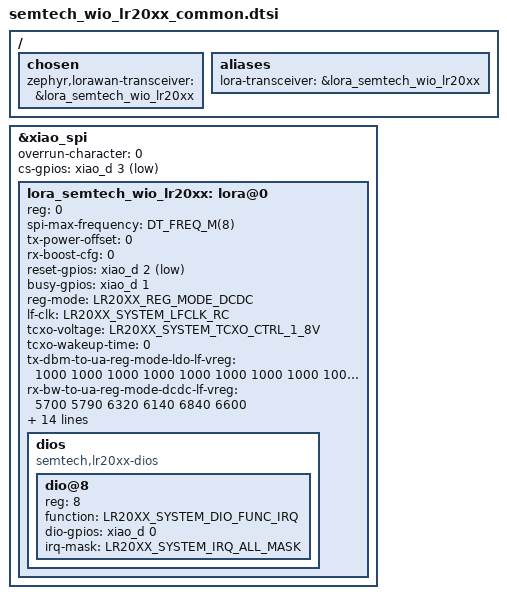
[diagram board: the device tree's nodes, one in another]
/*
 * Copyright (c) 2025 Semtech Corporation
 *
 * SPDX-License-Identifier: Apache-2.0
 */

#include <zephyr/dt-bindings/usp/lr20xx.h>

/ {
	chosen {
		zephyr,lorawan-transceiver = &lora_semtech_wio_lr20xx;
	};
	aliases {
		lora-transceiver = &lora_semtech_wio_lr20xx;
	};
};

&xiao_spi {
	status = "okay";
	overrun-character = <0>; // Defines state of MOSI when SPI RX
	cs-gpios = <&xiao_d 3 GPIO_ACTIVE_LOW>;

	lora_semtech_wio_lr20xx: lora@0 {
		reg = <0>;
		spi-max-frequency = <DT_FREQ_M(8)>;

		// Board-specific offset
		tx-power-offset = <0>;

		// RX boost offset, from 0 (no RX boost) to 7 (max RX boost)
		rx-boost-cfg = <0>;

		reset-gpios = <&xiao_d 2 GPIO_ACTIVE_LOW>; //D2

		busy-gpios = <&xiao_d 1 (GPIO_ACTIVE_HIGH | GPIO_PULL_UP)>; //D1

		reg-mode = <LR20XX_REG_MODE_DCDC>;

		lf-clk = <LR20XX_SYSTEM_LFCLK_RC>;

		tcxo-voltage = <LR20XX_SYSTEM_TCXO_CTRL_1_8V>;
		tcxo-wakeup-time = <0>;

		// LDO mode, LF path, NOT MEASed
		tx-dbm-to-ua-reg-mode-ldo-lf-vreg = <
		1000  /* -10 dBm */
		1000  /*  -9 dBm */
		1000  /*  -8 dBm */
		1000  /*  -7 dBm */
		1000  /*  -6 dBm */
		1000  /*  -5 dBm */
		1000  /*  -4 dBm */
		1000  /*  -3 dBm */
		1000  /*  -2 dBm */
		1000  /*  -1 dBm */
		1000  /*   0 dBm */
		1000  /*   1 dBm */
		1000  /*   2 dBm */
		1000  /*   3 dBm */
		1000  /*   4 dBm */
		1000  /*   5 dBm */
		1000  /*   6 dBm */
		1000  /*   7 dBm */
		1000  /*   8 dBm */
		1000  /*   9 dBm */
		1000  /*  10 dBm */
		1000  /*  11 dBm */
		1000  /*  12 dBm */
		1000  /*  13 dBm */
		1000  /*  14 dBm */
		1000  /*  15 dBm */
		1000  /*  16 dBm */
		1000  /*  17 dBm */
		1000  /*  18 dBm */
		1000  /*  19 dBm */
		1000  /*  20 dBm */
		1000  /*  21 dBm */
		1000  /*  22 dBm */
		>;

		// RX LoRa tables
		// Measured @LR20XX_RADIO_COMMON_RX_PATH_BOOST_MODE_NONE
		rx-bw-to-ua-reg-mode-dcdc-lf-vreg = <
		5700  /* RAL_LORA_BW_125_KHZ */
		5790  /* RAL_LORA_BW_250_KHZ */
		6320  /* RAL_LORA_BW_400_KHZ */
		6140  /* RAL_LORA_BW_500_KHZ */
		6840  /* RAL_LORA_BW_800_KHZ */
		6600  /* RAL_LORA_BW_1000_KHZ */
		>;

		rx-bw-to-ua-reg-mode-dcdc-hf-vreg = <
		6400  /* RAL_LORA_BW_125_KHZ */
		6510  /* RAL_LORA_BW_250_KHZ */
		7040  /* RAL_LORA_BW_400_KHZ */
		6860  /* RAL_LORA_BW_500_KHZ */
		6880  /* RAL_LORA_BW_800_KHZ */
		7350  /* RAL_LORA_BW_1000_KHZ */
		>;

		// Measured @LR20XX_RADIO_COMMON_RX_PATH_BOOST_MODE_7
		rx-bw-to-ua-reg-mode-dcdc-lf-vreg-boosted = <
		6920  /* RAL_LORA_BW_125_KHZ */
		6990  /* RAL_LORA_BW_250_KHZ */
		7530  /* RAL_LORA_BW_400_KHZ */
		7370  /* RAL_LORA_BW_500_KHZ */
		8160  /* RAL_LORA_BW_800_KHZ */
		7820  /* RAL_LORA_BW_1000_KHZ */
		>;

		rx-bw-to-ua-reg-mode-dcdc-hf-vreg-boosted = <
		6740  /* RAL_LORA_BW_125_KHZ */
		6850  /* RAL_LORA_BW_250_KHZ */
		7130  /* RAL_LORA_BW_400_KHZ */
		7180  /* RAL_LORA_BW_500_KHZ */
		8010  /* RAL_LORA_BW_800_KHZ */
		7690  /* RAL_LORA_BW_1000_KHZ */
		>;

		rx-bw-to-ua-reg-mode-ldo-lf-vreg = <
		9420   /* RAL_LORA_BW_125_KHZ */
		9580   /* RAL_LORA_BW_250_KHZ */
		10580  /* RAL_LORA_BW_400_KHZ */
		10240  /* RAL_LORA_BW_500_KHZ */
		11770  /* RAL_LORA_BW_800_KHZ */
		11130  /* RAL_LORA_BW_1000_KHZ */
		>;

		rx-bw-to-ua-reg-mode-ldo-hf-vreg = <
		10760  /* RAL_LORA_BW_125_KHZ */
		10890  /* RAL_LORA_BW_250_KHZ */
		11870  /* RAL_LORA_BW_400_KHZ */
		11640  /* RAL_LORA_BW_500_KHZ */
		13130  /* RAL_LORA_BW_800_KHZ */
		12500  /* RAL_LORA_BW_1000_KHZ */
		>;

		rx-bw-to-ua-reg-mode-ldo-lf-vreg-boosted = <
		11670  /* RAL_LORA_BW_125_KHZ */
		11710  /* RAL_LORA_BW_250_KHZ */
		12880  /* RAL_LORA_BW_400_KHZ */
		12560  /* RAL_LORA_BW_500_KHZ */
		14090  /* RAL_LORA_BW_800_KHZ */
		13500  /* RAL_LORA_BW_1000_KHZ */
		>;

		rx-bw-to-ua-reg-mode-ldo-hf-vreg-boosted = <
		11410  /* RAL_LORA_BW_125_KHZ */
		11570  /* RAL_LORA_BW_250_KHZ */
		12590  /* RAL_LORA_BW_400_KHZ */
		12280  /* RAL_LORA_BW_500_KHZ */
		13720  /* RAL_LORA_BW_800_KHZ */
		13180  /* RAL_LORA_BW_1000_KHZ */
		>;

		dios {
			compatible = "semtech,lr20xx-dios";
			#address-cells = <1>;
			#size-cells = <0>;
			dio@8 {
				reg = <8>;
				function = <LR20XX_SYSTEM_DIO_FUNC_IRQ>;
				dio-gpios = <&xiao_d 0 (GPIO_ACTIVE_HIGH | GPIO_PULL_DOWN)>; //D0
				irq-mask = <LR20XX_SYSTEM_IRQ_ALL_MASK>;
			};
		};
	};
};
